# Cortex_M7 register map
Vendor: Arm Ltd.; Series: ARMv7E-M; File version: 1.0.0
CPU: CM7 r0p0, little endian, MPU, FPU, double-precision FPU, DSP, 8 interrupt priority bits
Registers are 32-bit, read-write, reset 0x0 unless marked. A register's access mark holds for its fields unless they carry their own. Offsets are from the block's base; [hi:lo] are bit positions; {n}, {i} and the like mark numbered series; 'fields as' and 'values as' point back to an identical list.

## NVIC — Nested Vectored Interrupt Controller: enable, pending, active and priority registers for the external interrupts (IRQ0 = exception 16) and the software trigger register. Bit k of register n refers to IRQ 32n+k.
Base 0xE000E100
{0x0+4i} ISER{i} (i=0..7) — Interrupt Set-Enable Register n (IRQ 32n..32n+31): write 1 to enable an interrupt, 0 has no effect; reads the enable state.
  [31:0] SETENA — Bit k: write 1 to enable IRQ 32n+k; reads 1 if enabled. Writing 0 has no effect.
{0x80+4i} ICER{i} (i=0..7) — Interrupt Clear-Enable Register n (IRQ 32n..32n+31): write 1 to disable an interrupt, 0 has no effect; reads the enable state.
  [31:0] CLRENA — Bit k: write 1 to disable IRQ 32n+k; reads 1 if enabled. Writing 0 has no effect.
{0x100+4i} ISPR{i} (i=0..7) — Interrupt Set-Pending Register n (IRQ 32n..32n+31): write 1 to set an interrupt pending; reads the pending state.
  [31:0] SETPEND — Bit k: write 1 to set IRQ 32n+k pending; reads 1 if pending.
{0x180+4i} ICPR{i} (i=0..7) — Interrupt Clear-Pending Register n (IRQ 32n..32n+31): write 1 to clear a pending interrupt; reads the pending state.
  [31:0] CLRPEND — Bit k: write 1 to clear IRQ 32n+k pending; reads 1 if pending.
{0x200+4i} IABR{i} (i=0..7) ro — Interrupt Active Bit Register n (IRQ 32n..32n+31): 1 = the interrupt handler is active (executing or preempted). Read-only.
  [31:0] ACTIVE — Bit k: 1 = the handler of IRQ 32n+k is active.
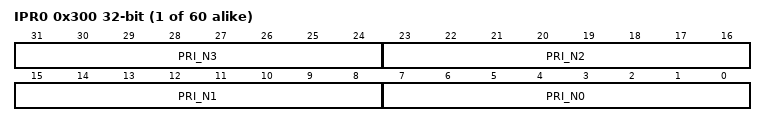
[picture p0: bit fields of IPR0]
{0x300+4i} IPR{i} (i=0..59) — Interrupt Priority Register n: one byte per interrupt, IRQ 4n+0 in bits [7:0] up to IRQ 4n+3 in [31:24]. Lower value = higher priority; only the top nvicPrioBits of each byte are implemented (ARMv6-M: 2, typical ARMv7-M: 3-4).
  [8n+7:8n] PRI_N{n} (n=0..3) — Priority of interrupt 4n+{n}. Only the top nvicPrioBits (implementation defined, 2 to 8) are implemented; the rest read as zero.
0xE00 STIR wo — Software Trigger Interrupt Register: writing an interrupt number sets that interrupt pending (like ISPR). Unprivileged writes need CCR.USERSETMPEND.
  [8:0] INTID — Interrupt number to set pending (0 = IRQ0, i.e. exception 16). Unprivileged writes are allowed when CCR.USERSETMPEND is 1.

## ERRBNK — Error Bank: records the location of ECC errors detected in the instruction cache, data cache and (Cortex-M55/M85) TCM RAMs, so software can scrub the location and diagnose failing RAM.
Base 0xE000EFB0
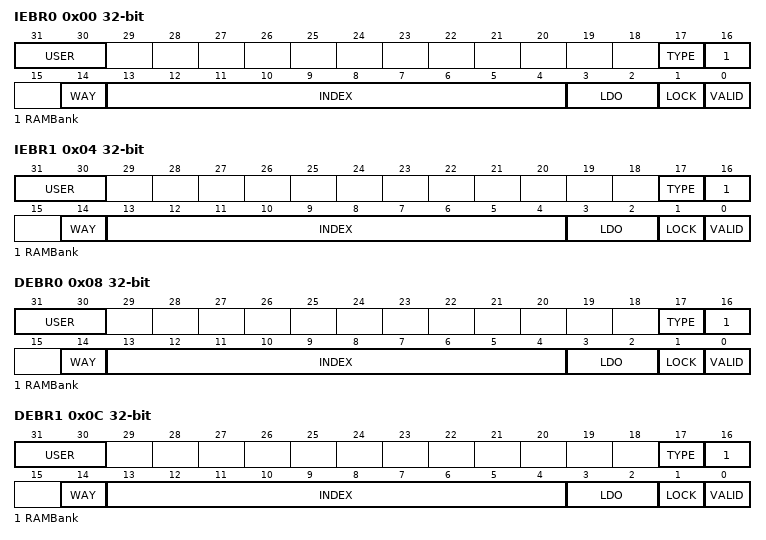
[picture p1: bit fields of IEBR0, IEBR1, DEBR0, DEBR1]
0x00 IEBR0 — Instruction Cache Error Bank Register 0: the first recorded I-cache ECC error.
  [31:30] USER — Software-defined bits (not used by hardware).
  [17] TYPE — Error type: 0 = data RAM, 1 = tag RAM.
  [16] RAMBank — RAM bank of the error (Cortex-M7).
  [14] WAY — Cache way of the error (Cortex-M7 2-way I-cache).
  [13:4] INDEX — Cache set index of the error (Cortex-M7).
  [3:2] LDO — Cortex-M7 error bank bits [3:2]; see the error bank register layout in the Cortex-M7 TRM.
  [1] LOCK — Locked: a further error occurred while this entry was valid; the entry keeps the first error until cleared.
  [0] VALID — Entry valid: an error has been recorded. Clear it after scrubbing the location.
0x04 IEBR1 — Instruction Cache Error Bank Register 1: the second recorded I-cache ECC error.
  fields as IEBR0
0x08 DEBR0 — Data Cache Error Bank Register 0: the first recorded D-cache ECC error.
  [31:30] USER — Software-defined bits (not used by hardware).
  [17] TYPE — Error type: 0 = data RAM, 1 = tag/dirty RAM.
  [16] RAMBank — RAM bank of the error (Cortex-M7).
  [14] WAY — Cache way of the error.
  [13:4] INDEX — Cache set index of the error (Cortex-M7).
  [3:2] LDO — Cortex-M7 error bank bits [3:2]; see the error bank register layout in the Cortex-M7 TRM.
  [1] LOCK — Locked: a further error occurred while this entry was valid; the entry keeps the first error until cleared.
  [0] VALID — Entry valid: an error has been recorded.
0x0C DEBR1 — Data Cache Error Bank Register 1: the second recorded D-cache ECC error.
  fields as DEBR0
